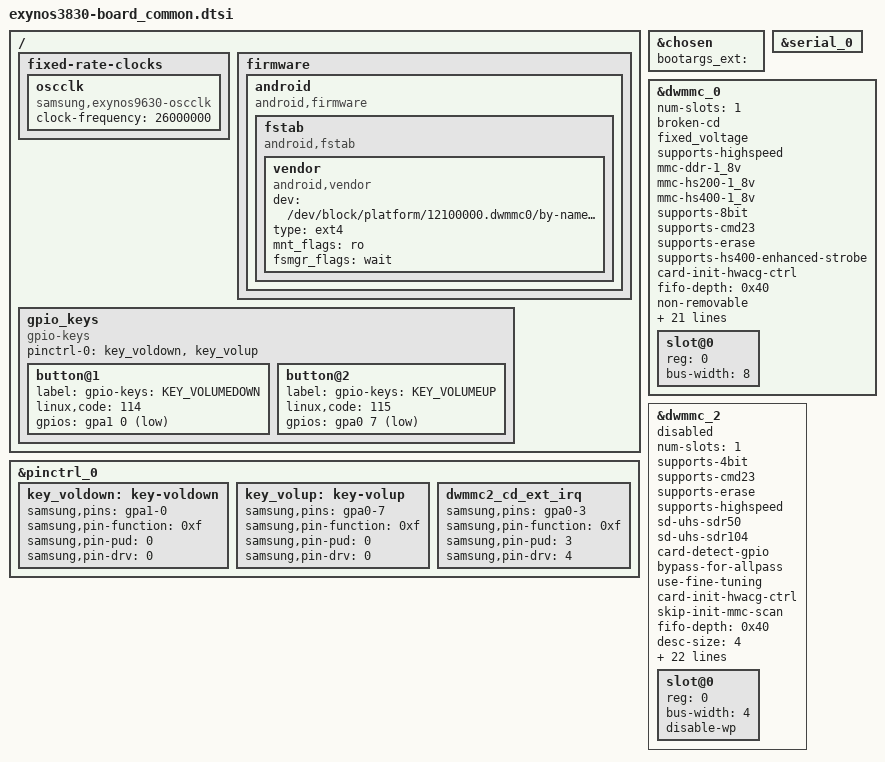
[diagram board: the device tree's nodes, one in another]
/*
 * SAMSUNG EXYNOS9630 board common device tree source
 *
 * Copyright (c) 2019 Samsung Electronics Co., Ltd.
 *		http://www.samsung.com
 *
 * This program is free software; you can redistribute it and/or modify
 * it under the terms of the GNU General Public License version 2 as
 * published by the Free Software Foundation.
 */

#include <dt-bindings/interrupt-controller/exynos3830.h>

/ {
	fragment@common {
		target-path = "/";
		__overlay__ {
			#address-cells = <2>;
			#size-cells = <1>;

			fixed-rate-clocks {
				oscclk {
					compatible = "samsung,exynos9630-oscclk";
					clock-frequency = <26000000>;
				};
			};

			firmware {
				android {
					compatible = "android,firmware";

					/* TODO: vbmeta */
					/*
					vbmeta {
						compatible = "android,vbmeta";
						parts = "vbmeta,boot,system,vendor,dtbo";
					};
					*/

					fstab {
						compatible = "android,fstab";
						vendor {
							compatible = "android,vendor";
							dev = "/dev/block/platform/12100000.dwmmc0/by-name/vendor";
							type = "ext4";
							mnt_flags = "ro";
							fsmgr_flags = "wait";
						};
					};
				};
			};

			gpio_keys {
				status = "okay";
				compatible = "gpio-keys";
				pinctrl-names = "default";
				pinctrl-0 = <&key_voldown &key_volup>;

				button@1 {
					label = "gpio-keys: KEY_VOLUMEDOWN";
					linux,code = <114>;
					gpios = <&gpa1 0 0xf>;
				};
				button@2 {
					label = "gpio-keys: KEY_VOLUMEUP";
					linux,code = <115>;
					gpios = <&gpa0 7 0xf>;
				};
			};
		}; /* end of __overlay__ */
	}; /* end of fragment */
}; /* end of root */

&chosen {
	bootargs_ext = "";
};

&serial_0 {
	status = "okay";
};

&pinctrl_0 {
	key_voldown: key-voldown {
		samsung,pins = "gpa1-0";
		samsung,pin-function = <0xf>;
		samsung,pin-pud = <0>;
		samsung,pin-drv = <0>;
	};

	key_volup: key-volup {
		samsung,pins = "gpa0-7";
		samsung,pin-function = <0xf>;
		samsung,pin-pud = <0>;
		samsung,pin-drv = <0>;
	};

	dwmmc2_cd_ext_irq: dwmmc2_cd_ext_irq {
		samsung,pins = "gpa0-3";
		samsung,pin-function = <0xf>;
		samsung,pin-pud = <3>;
		samsung,pin-drv = <4>;
	};
};

&dwmmc_0 {
	status = "okay";
	num-slots = <1>;
	broken-cd;
	fixed_voltage;
	supports-highspeed;
	mmc-ddr-1_8v;
	mmc-hs200-1_8v;
	mmc-hs400-1_8v;
	supports-8bit;
	supports-cmd23;
	supports-erase;
	supports-hs400-enhanced-strobe;
	card-init-hwacg-ctrl;
	fifo-depth = <0x40>;
	non-removable;
	desc-size = <4>;
	card-detect-delay = <200>;
	samsung,dw-mshc-ciu-div = <3>;
	samsung,dw-mshc-txdt-crc-timer-fastlimit = <0x13>;
	samsung,dw-mshc-txdt-crc-timer-initval = <0x15>;
	samsung,dw-mshc-hs400-delay-line = <0x60>;
	samsung,dw-mshc-sdr-timing = <3 0 4 0>;
	samsung,dw-mshc-ddr-timing = <3 0 4 2>;
	samsung,dw-mshc-hs200-timing = <3 0 3 0>;
	samsung,dw-mshc-hs400-timing = <1 0 2 0>;
	samsung,dw-mshc-hs400-ulp-timing = <3 0 2 0>;

	num-ref-clks = <12>;
	ciu_clkin = <25 50 50 25 50 100 200 50 50 200 200 200>;

	/* Swapping clock drive strength */
	clk-drive-number = <4>;
	pinctrl-names = "default",
		"fast-slew-rate-1x",
		"fast-slew-rate-2x",
		"fast-slew-rate-3x",
		"fast-slew-rate-4x";
	pinctrl-0 = <&sd0_clk &sd0_cmd &sd0_rdqs &sd0_bus1 &sd0_bus4 &sd0_bus8>;
	pinctrl-1 = <&sd0_clk_fast_slew_rate_1x>;
	pinctrl-2 = <&sd0_clk_fast_slew_rate_2x>;
	pinctrl-3 = <&sd0_clk_fast_slew_rate_3x>;
	pinctrl-4 = <&sd0_clk_fast_slew_rate_4x>;

	slot@0 {
		reg = <0>;
		bus-width = <8>;
	};

};

&dwmmc_2 {
	#address-cells = <1>;
	#size-cells = <0>;
	status = "disabled";
	num-slots = <1>;
	supports-4bit;
	supports-cmd23;
	supports-erase;
	supports-highspeed;
	sd-uhs-sdr50;
	sd-uhs-sdr104;
	card-detect-gpio;
	bypass-for-allpass;
	use-fine-tuning;
	card-init-hwacg-ctrl;
	skip-init-mmc-scan;
	fifo-depth = <0x40>;
	desc-size = <4>;
	card-detect-delay = <200>;
	samsung,dw-mshc-ciu-div = <3>;
	clock-frequency = <800000000>;
	samsung,dw-mshc-sdr-timing = <3 0 2 0>;
	samsung,dw-mshc-ddr-timing = <3 0 2 1>;
	samsung,dw-mshc-sdr50-timing = <3 0 4 2>;
	samsung,dw-mshc-sdr104-timing = <3 0 3 0>;

	num-ref-clks = <9>;
	ciu_clkin = <25 50 50 25 50 100 200 50 50>;

	/* Swapping clock drive strength */
	clk-drive-number = <6>;
	pinctrl-names = "default",
		"fast-slew-rate-1x",
		"fast-slew-rate-1_5x",
		"fast-slew-rate-2x",
		"fast-slew-rate-2_5x",
		"fast-slew-rate-3x",
		"fast-slew-rate-4x",
		"pins-as-pdn",
		"pins-as-func";
	pinctrl-0 = <&sd2_clk &sd2_cmd &sd2_bus1 &sd2_bus4 &dwmmc2_cd_ext_irq>;
	pinctrl-1 = <&sd2_clk_fast_slew_rate_1x>;
	pinctrl-2 = <&sd2_clk_fast_slew_rate_1_5x>;
	pinctrl-3 = <&sd2_clk_fast_slew_rate_2x>;
	pinctrl-4 = <&sd2_clk_fast_slew_rate_2_5x>;
	pinctrl-5 = <&sd2_clk_fast_slew_rate_3x>;
	pinctrl-6 = <&sd2_clk_fast_slew_rate_4x>;
	pinctrl-7 = <&sd2_pins_as_pdn>;
	pinctrl-8 = <&sd2_clk &sd2_cmd &sd2_bus1 &sd2_bus4>;

	card-detect = <&gpa0 3 0xf>;
	slot@0 {
		reg = <0>;
		bus-width = <4>;
		disable-wp;
	};
};

/* TODO Add TSP */
/*
&hsi2c_6 {
	#address-cells = <1>;
	#size-cells = <0>;
	status = "okay";
	samsung,reset-before-trans;
	touchscreen@48 {
		compatible = "sec,sec_ts";
		reg = <0x48>;
		pinctrl-names = "on_state", "off_state";
		pinctrl-0 = <&attn_irq &vdd_on>;
		pinctrl-1 = <&attn_input &vdd_off>;
		pressure-sensor = "Y";
		sec,irq_gpio = <&gpa0 3 0>;
		sec,irq_type = <8200>;
		sec,max_coords = <4095 4095>;
		sec,mis_cal_check = <1>;
//		sec,regulator_avdd = "";
//		sec,regulator_boot_on;
//		sec,always_lpmode = <1>;
		sec,project_name = "neus";
		sec,firmware_name = "tsp_sec/y761_dream1.fw", "tsp_sec/y761_dream1.fw";
	};
};
*/
